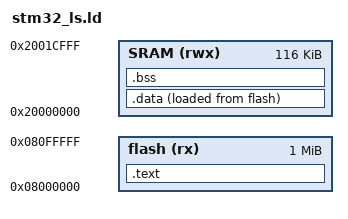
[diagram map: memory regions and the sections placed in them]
ENTRY(reset_handler)

MEMORY{

    flash(rx):ORIGIN =0x08000000,LENGTH =1024K
    SRAM(rwx):ORIGIN =0x20000000,LENGTH =116K
}

SECTIONS{
    .text : 
    {   *(.isr_vector)
        *(.text)
        *(.rodata)
        . = ALIGN(4);
        _etext = .;
    }> flash
    .data :
    {   _sdata = .;
        *(.data)
        . = ALIGN(4);
        _edata = .;
    }> SRAM AT> flash

    .bss :
    {   _sbss = .;
        *(.bss)
        . = ALIGN(4);
        _ebss = .;
    }> SRAM
}
